# VPAC0_PAR_VPAC_VISS0_S_VBUSP_VISS_FCP_EE_VBUSP_FLEXEE register map
Vendor: Texas Instruments
Peripheral module from a debugger description file (folder J7ES).
Registers are 32-bit, read-write, reset 0x0 unless marked. A register's access mark holds for its fields unless they carry their own. Offsets are as the file gives them; lines under a group give offsets from that group; [hi:lo] are bit positions; {n}, {i} and the like mark numbered series; 'fields as' and 'values as' point back to an identical list; <NAME> marks a mode.

## VPAC0_PAR_VPAC_VISS0_S_VBUSP_VISS_FCP_EE_VBUSP_FLEXEE
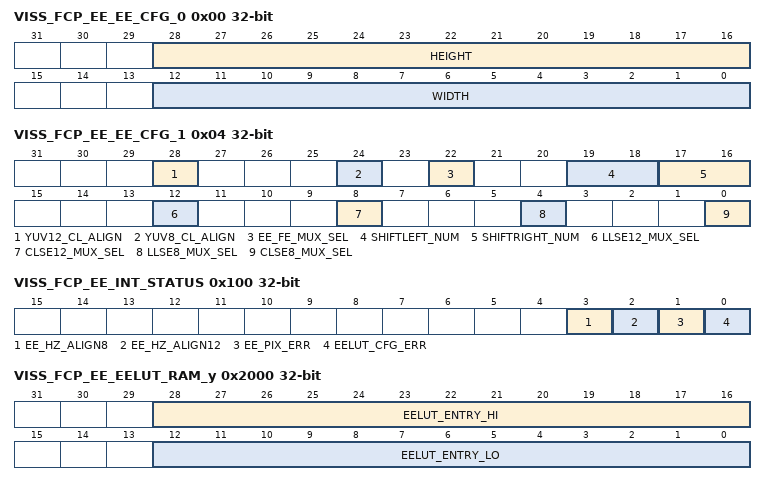
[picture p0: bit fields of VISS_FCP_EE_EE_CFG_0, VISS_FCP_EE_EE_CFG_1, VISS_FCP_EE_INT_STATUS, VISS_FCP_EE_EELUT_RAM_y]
0x00 VISS_FCP_EE_EE_CFG_0 — The Control Register controls the input width and height of the module.
  [28:16] HEIGHT — Height of the input image
  [12:0] WIDTH — Width of the input image
0x04 VISS_FCP_EE_EE_CFG_1 — The CEE route config Register controls the routing of trafic through and around the EE.
  [28] YUV12_CL_ALIGN — Enables the alignment of the Chroma and Luma for the yuv12 stream.
  [24] YUV8_CL_ALIGN — Enables the alignment of the Chroma and Luma for the yuv8 stream.
  [22] EE_FE_MUX_SEL — Selects which data stream to pass through the EE block.
  [19:18] SHIFTLEFT_NUM — Sects the amount to shift left the incoming pixel to the EE block.
  [17:16] SHIFTRIGHT_NUM — Sects the amount to shift right the outgoing pixel from the EE block.
  [12] LLSE12_MUX_SEL — Selects Luma stream for the yuv12 output.
  [8] CLSE12_MUX_SEL — Selects Chroma stream for the yuv12 output.
  [4] LLSE8_MUX_SEL — Selects Luma stream for the yuv8 output.
  [0] CLSE8_MUX_SEL — Selects Chroma stream for the yuv8 output.
0x08 VISS_FCP_EE_EE_ENABLE — The EE Enable register control the internal bypass of the EE block.
  [0] YEE_ENABLE
0x0C VISS_FCP_EE_YEE_SHIFT — The YEE Shift register controls
  [5:0] YEE_SHIFT
{0x10+0x10*i} VISS_FCP_EE_YEE_COEF_R{i}_C0 (i=0..2) — The YEE Coefficient Row x Column x defines the
  [9:0] YEE_COEF_R{i}_C0 — The
{0x14+0x10*i} VISS_FCP_EE_YEE_COEF_R{i}_C1 (i=0..2) — The YEE Coefficient Row x Column x defines the
  [9:0] YEE_COEF_R{i}_C1 — The
{0x18+0x10*i} VISS_FCP_EE_YEE_COEF_R{i}_C2 (i=0..2) — The YEE Coefficient Row x Column x defines the
  [9:0] YEE_COEF_R{i}_C2 — The
0x40 VISS_FCP_EE_YEE_E_THR — The
  [9:0] YEE_E_THR
0x44 VISS_FCP_EE_YEE_MERGESEL — The Merge selects the output that is added to the target pixel.
  [0] YEE_MERGESEL — The
0x48 VISS_FCP_EE_YES_E_HAL — The Halo selects Halo reduction mode.
  [0] YES_E_HAL — The
0x4C VISS_FCP_EE_YES_G_GAIN — The
  [7:0] YES_G_GAIN — The Gradient Gain
0x50 VISS_FCP_EE_YES_E_GAIN — The
  [11:0] YES_E_GAIN — The Band-pass filter gain
0x54 VISS_FCP_EE_YES_E_THR1 — The
  [15:0] YES_E_THR1 — The shrink threshold
0x58 VISS_FCP_EE_YES_E_THR2 — The
  [9:0] YES_E_THR2 — The clip threshold
0x5C VISS_FCP_EE_YES_G_OFT — The
  [9:0] YES_G_OFT — The offset applied to the Gradient gain
0x100 VISS_FCP_EE_INT_STATUS access not given — Status/clear register for flexee interrupts
  [3] EE_HZ_ALIGN8 — status/clear for EE horizontal aligner yuv8 overflow error indicates that the luma and chroma line starts were not within hardware synchronization limits. (access RW1C)
  [2] EE_HZ_ALIGN12 — status/clear for EE horizontal aligner yuv12 overflow error indicates that the luma and chroma line starts were not within hardware synchronization limits. (access RW1C)
  [1] EE_PIX_ERR — status/clear for error on line array, set when software accesses EE pixel array during active frame causing potential frame corruption. (access RW1C)
  [0] EELUT_CFG_ERR — status/clear for error on EE LUT cfg, set when software accesses EE LUT during active frame causing potential frame corruption. (access RW1C)
0x1008 VISS_FCP_EE_LINE_SEL — Selector for which line memory is read or written
  [2:0] LINE_SELECTOR — Selects which line is read or written from the line memory array.
0x2000 VISS_FCP_EE_EELUT_RAM_y — The host will program the EE LUT RAM so that the pixels are translated from 14 bit to 12 bit using LUT entries. Offset = 000D2000h + (y * 4h); where y = 0h to 7FFh
  [28:16] EELUT_ENTRY_HI — The lower EE LUT entry n+1.
  [12:0] EELUT_ENTRY_LO — The lower EE LUT entry n+0.
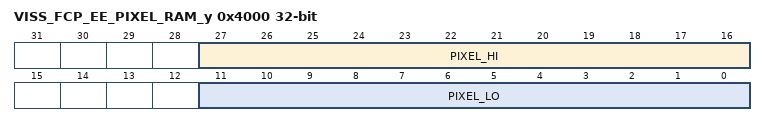
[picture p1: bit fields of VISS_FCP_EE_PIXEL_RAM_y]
0x4000 VISS_FCP_EE_PIXEL_RAM_y — The pixel RAM contains the array of 12 bit pixels stored and used by the CFA logic. Pixels are 16 bit aligned. Pixels can only be written two at a time. Offset = 000D4000h + (y * 4h); where y = 0h to 7FFh
  [27:16] PIXEL_HI — The 12 bit pixel data for the selected line upper pixel 'n+1'
  [11:0] PIXEL_LO — The 12 bit pixel data for the selected line lower pixel 'n'
